AUTOSAR XML (schema 4-2-2)
package /ComponentTypes
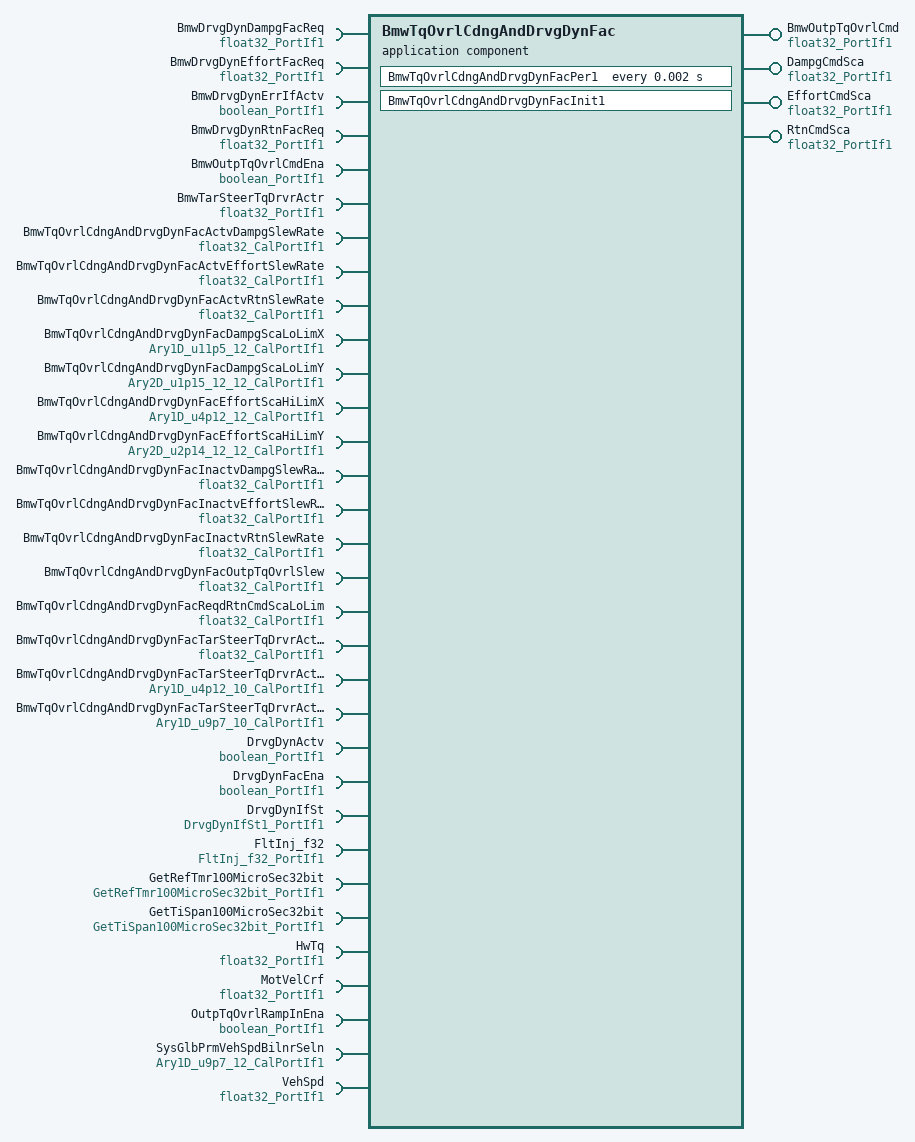
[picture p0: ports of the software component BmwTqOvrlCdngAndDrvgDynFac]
  application sw component type BmwTqOvrlCdngAndDrvgDynFac
    4 x provide port, all with provided-interface=float32_PortIf1:
      BmwOutpTqOvrlCmd: nonqueued-sender-com-spec{data-element=Val, init-value=0}
      DampgCmdSca: nonqueued-sender-com-spec{data-element=Val, init-value=1}
      EffortCmdSca: nonqueued-sender-com-spec{data-element=Val, init-value=1}
      RtnCmdSca: nonqueued-sender-com-spec{data-element=Val, init-value=1}
    32 x require port:
      BmwDrvgDynDampgFacReq: nonqueued-receiver-com-spec{data-element=Val, filter=data-filter-type=ALWAYS, init-value=1}, required-interface=float32_PortIf1
      BmwDrvgDynEffortFacReq: nonqueued-receiver-com-spec{data-element=Val, filter=data-filter-type=ALWAYS, init-value=1}, required-interface=float32_PortIf1
      BmwDrvgDynErrIfActv: nonqueued-receiver-com-spec{data-element=Logl, filter=data-filter-type=ALWAYS, init-value=0}, required-interface=boolean_PortIf1
      BmwDrvgDynRtnFacReq: nonqueued-receiver-com-spec{data-element=Val, filter=data-filter-type=ALWAYS, init-value=1}, required-interface=float32_PortIf1
      BmwOutpTqOvrlCmdEna: nonqueued-receiver-com-spec{data-element=Logl, filter=data-filter-type=ALWAYS, init-value=1}, required-interface=boolean_PortIf1
      BmwTarSteerTqDrvrActr: nonqueued-receiver-com-spec{data-element=Val, filter=data-filter-type=ALWAYS, init-value=0}, required-interface=float32_PortIf1
      BmwTqOvrlCdngAndDrvgDynFacActvDampgSlewRate: parameter-require-com-spec{init-value=500, parameter=Val}, required-interface=float32_CalPortIf1
      BmwTqOvrlCdngAndDrvgDynFacActvEffortSlewRate: parameter-require-com-spec{init-value=500, parameter=Val}, required-interface=float32_CalPortIf1
      BmwTqOvrlCdngAndDrvgDynFacActvRtnSlewRate: parameter-require-com-spec{init-value=500, parameter=Val}, required-interface=float32_CalPortIf1
      BmwTqOvrlCdngAndDrvgDynFacDampgScaLoLimX: parameter-require-com-spec{init-value=[0, 1164, 2327, 3491, 4655, 5818, 6982, 8145, 9309, 10473, 11636, 12800], parameter=Ary1D}, required-interface=Ary1D_u11p5_12_CalPortIf1
      BmwTqOvrlCdngAndDrvgDynFacDampgScaLoLimY: parameter-require-com-spec{init-value=12 x 12 x 0, parameter=Ary2D}, required-interface=Ary2D_u1p15_12_12_CalPortIf1
      BmwTqOvrlCdngAndDrvgDynFacEffortScaHiLimX: parameter-require-com-spec{init-value=[0, 3724, 7447, 11171, 14895, 18618, 22342, 26065, 29789, 33513, 37236, 40960], parameter=Ary1D}, required-interface=Ary1D_u4p12_12_CalPortIf1
      BmwTqOvrlCdngAndDrvgDynFacEffortScaHiLimY: parameter-require-com-spec{init-value=12 x 12 x 32768, parameter=Ary2D}, required-interface=Ary2D_u2p14_12_12_CalPortIf1
      BmwTqOvrlCdngAndDrvgDynFacInactvDampgSlewRate: parameter-require-com-spec{init-value=500, parameter=Val}, required-interface=float32_CalPortIf1
      BmwTqOvrlCdngAndDrvgDynFacInactvEffortSlewRate: parameter-require-com-spec{init-value=500, parameter=Val}, required-interface=float32_CalPortIf1
      BmwTqOvrlCdngAndDrvgDynFacInactvRtnSlewRate: parameter-require-com-spec{init-value=500, parameter=Val}, required-interface=float32_CalPortIf1
      BmwTqOvrlCdngAndDrvgDynFacOutpTqOvrlSlew: parameter-require-com-spec{init-value=2, parameter=Val}, required-interface=float32_CalPortIf1
      BmwTqOvrlCdngAndDrvgDynFacReqdRtnCmdScaLoLim: parameter-require-com-spec{init-value=0, parameter=Val}, required-interface=float32_CalPortIf1
      BmwTqOvrlCdngAndDrvgDynFacTarSteerTqDrvrActrLpFilFrq: parameter-require-com-spec{init-value=0.3, parameter=Val}, required-interface=float32_CalPortIf1
      BmwTqOvrlCdngAndDrvgDynFacTarSteerTqDrvrActrMaxY: parameter-require-com-spec{init-value=[14336, 12288, 10240, 8192, 6144, 4096, 3072, 2048, 1024, 410], parameter=Ary1D}, required-interface=Ary1D_u4p12_10_CalPortIf1
      BmwTqOvrlCdngAndDrvgDynFacTarSteerTqDrvrActrSpdX: parameter-require-com-spec{init-value=[0, 256, 1280, 3200, 6400, 9600, 12800, 19200, 25600, 31872], parameter=Ary1D}, required-interface=Ary1D_u9p7_10_CalPortIf1
      DrvgDynActv: nonqueued-receiver-com-spec{data-element=Logl, filter=data-filter-type=ALWAYS, init-value=0}, required-interface=boolean_PortIf1
      DrvgDynFacEna: nonqueued-receiver-com-spec{data-element=Logl, filter=data-filter-type=ALWAYS, init-value=1}, required-interface=boolean_PortIf1
      DrvgDynIfSt: nonqueued-receiver-com-spec{data-element=Val, filter=data-filter-type=ALWAYS, init-value=128}, required-interface=DrvgDynIfSt1_PortIf1
      FltInj_f32: client-com-spec=Oper, required-interface=FltInj_f32_PortIf1
      GetRefTmr100MicroSec32bit: client-com-spec=Oper, required-interface=GetRefTmr100MicroSec32bit_PortIf1
      GetTiSpan100MicroSec32bit: client-com-spec=Oper, required-interface=GetTiSpan100MicroSec32bit_PortIf1
      HwTq: nonqueued-receiver-com-spec{data-element=Val, filter=data-filter-type=ALWAYS, init-value=0}, required-interface=float32_PortIf1
      MotVelCrf: nonqueued-receiver-com-spec{data-element=Val, filter=data-filter-type=ALWAYS, init-value=0}, required-interface=float32_PortIf1
      OutpTqOvrlRampInEna: nonqueued-receiver-com-spec{data-element=Logl, filter=data-filter-type=ALWAYS, init-value=0}, required-interface=boolean_PortIf1
      SysGlbPrmVehSpdBilnrSeln: parameter-require-com-spec{init-value=[0, 640, 1920, 3840, 7680, 10240, 12800, 15360, 19200, 23040, 25600, 28160], parameter=Ary1D}, required-interface=Ary1D_u9p7_12_CalPortIf1
      VehSpd: nonqueued-receiver-com-spec{data-element=Val, filter=data-filter-type=ALWAYS, init-value=0}, required-interface=float32_PortIf1
    behavior cf40a_InternalBehavior
      ar-typed-per-instance-memorys:
        16 x data, all with sw-calibration-access=READ-ONLY:
          BmwOutpTqOvrlCmdRampCmpl: type=boolean
          BmwOutpTqOvrlCmdStVari: type=float32
          BmwTarSteerTqDrvrActrLpFilStVari: type=FilLpRec1
          DampgCmdScaRateLimrStVari: type=float32
          EffortCmdScaRateLimrStVari: type=float32
          FrznBmwTarSteerTqDrvrActr: type=float32
          FrznSigActv: type=boolean
          LimdCdndTqOvrl: type=float32
          MsgCycTmr: type=uint32
          PrevDampgSlewInProgs: type=boolean
          PrevDrvgDynActv: type=boolean
          PrevDrvgDynIfSt: type=DrvgDynIfSt1
          PrevEffortSlewInProgs: type=boolean
          PrevRtnSlewInProgs: type=boolean
          RampToZeroEnad: type=boolean
          RtnCmdScaRateLimrStVari: type=float32
      init event BmwTqOvrlCdngAndDrvgDynFacInit1_InitEvent: start-on-event=BmwTqOvrlCdngAndDrvgDynFacInit1
      timing event TMT_BmwTqOvrlCdngAndDrvgDynFacPer1: start-on-event=BmwTqOvrlCdngAndDrvgDynFacPer1, period=0.002
      port-api-options:
        enable-take-address=false, error-handling=NO-TRANSFORMER-ERROR-HANDLING, indirect-api=false, port=BmwDrvgDynDampgFacReq
        enable-take-address=false, error-handling=NO-TRANSFORMER-ERROR-HANDLING, indirect-api=false, port=BmwDrvgDynEffortFacReq
        enable-take-address=false, error-handling=NO-TRANSFORMER-ERROR-HANDLING, indirect-api=false, port=BmwDrvgDynErrIfActv
        enable-take-address=false, error-handling=NO-TRANSFORMER-ERROR-HANDLING, indirect-api=false, port=BmwDrvgDynRtnFacReq
        enable-take-address=false, error-handling=NO-TRANSFORMER-ERROR-HANDLING, indirect-api=false, port=BmwOutpTqOvrlCmd
        enable-take-address=false, error-handling=NO-TRANSFORMER-ERROR-HANDLING, indirect-api=false, port=BmwOutpTqOvrlCmdEna
        enable-take-address=false, error-handling=NO-TRANSFORMER-ERROR-HANDLING, indirect-api=false, port=BmwTarSteerTqDrvrActr
        enable-take-address=false, error-handling=NO-TRANSFORMER-ERROR-HANDLING, indirect-api=false, port=BmwTqOvrlCdngAndDrvgDynFacActvDampgSlewRate
        enable-take-address=false, error-handling=NO-TRANSFORMER-ERROR-HANDLING, indirect-api=false, port=BmwTqOvrlCdngAndDrvgDynFacActvEffortSlewRate
        enable-take-address=false, error-handling=NO-TRANSFORMER-ERROR-HANDLING, indirect-api=false, port=BmwTqOvrlCdngAndDrvgDynFacActvRtnSlewRate
        enable-take-address=false, error-handling=NO-TRANSFORMER-ERROR-HANDLING, indirect-api=false, port=BmwTqOvrlCdngAndDrvgDynFacDampgScaLoLimX
        enable-take-address=false, error-handling=NO-TRANSFORMER-ERROR-HANDLING, indirect-api=false, port=BmwTqOvrlCdngAndDrvgDynFacDampgScaLoLimY
        enable-take-address=false, error-handling=NO-TRANSFORMER-ERROR-HANDLING, indirect-api=false, port=BmwTqOvrlCdngAndDrvgDynFacEffortScaHiLimX
        enable-take-address=false, error-handling=NO-TRANSFORMER-ERROR-HANDLING, indirect-api=false, port=BmwTqOvrlCdngAndDrvgDynFacEffortScaHiLimY
        enable-take-address=false, error-handling=NO-TRANSFORMER-ERROR-HANDLING, indirect-api=false, port=BmwTqOvrlCdngAndDrvgDynFacInactvDampgSlewRate
        enable-take-address=false, error-handling=NO-TRANSFORMER-ERROR-HANDLING, indirect-api=false, port=BmwTqOvrlCdngAndDrvgDynFacInactvEffortSlewRate
        enable-take-address=false, error-handling=NO-TRANSFORMER-ERROR-HANDLING, indirect-api=false, port=BmwTqOvrlCdngAndDrvgDynFacInactvRtnSlewRate
        enable-take-address=false, error-handling=NO-TRANSFORMER-ERROR-HANDLING, indirect-api=false, port=BmwTqOvrlCdngAndDrvgDynFacOutpTqOvrlSlew
        enable-take-address=false, error-handling=NO-TRANSFORMER-ERROR-HANDLING, indirect-api=false, port=BmwTqOvrlCdngAndDrvgDynFacReqdRtnCmdScaLoLim
        enable-take-address=false, error-handling=NO-TRANSFORMER-ERROR-HANDLING, indirect-api=false, port=BmwTqOvrlCdngAndDrvgDynFacTarSteerTqDrvrActrLpFilFrq
        enable-take-address=false, error-handling=NO-TRANSFORMER-ERROR-HANDLING, indirect-api=false, port=BmwTqOvrlCdngAndDrvgDynFacTarSteerTqDrvrActrMaxY
        enable-take-address=false, error-handling=NO-TRANSFORMER-ERROR-HANDLING, indirect-api=false, port=BmwTqOvrlCdngAndDrvgDynFacTarSteerTqDrvrActrSpdX
        enable-take-address=false, error-handling=NO-TRANSFORMER-ERROR-HANDLING, indirect-api=false, port=DampgCmdSca
        enable-take-address=false, error-handling=NO-TRANSFORMER-ERROR-HANDLING, indirect-api=false, port=DrvgDynActv
        enable-take-address=false, error-handling=NO-TRANSFORMER-ERROR-HANDLING, indirect-api=false, port=DrvgDynFacEna
        enable-take-address=false, error-handling=NO-TRANSFORMER-ERROR-HANDLING, indirect-api=false, port=DrvgDynIfSt
        enable-take-address=false, error-handling=NO-TRANSFORMER-ERROR-HANDLING, indirect-api=false, port=EffortCmdSca
        enable-take-address=false, error-handling=NO-TRANSFORMER-ERROR-HANDLING, indirect-api=false, port=FltInj_f32
        enable-take-address=false, error-handling=NO-TRANSFORMER-ERROR-HANDLING, indirect-api=false, port=GetRefTmr100MicroSec32bit
        enable-take-address=false, error-handling=NO-TRANSFORMER-ERROR-HANDLING, indirect-api=false, port=GetTiSpan100MicroSec32bit
        enable-take-address=false, error-handling=NO-TRANSFORMER-ERROR-HANDLING, indirect-api=false, port=HwTq
        enable-take-address=false, error-handling=NO-TRANSFORMER-ERROR-HANDLING, indirect-api=false, port=MotVelCrf
        enable-take-address=false, error-handling=NO-TRANSFORMER-ERROR-HANDLING, indirect-api=false, port=OutpTqOvrlRampInEna
        enable-take-address=false, error-handling=NO-TRANSFORMER-ERROR-HANDLING, indirect-api=false, port=RtnCmdSca
        enable-take-address=false, error-handling=NO-TRANSFORMER-ERROR-HANDLING, indirect-api=false, port=SysGlbPrmVehSpdBilnrSeln
        enable-take-address=false, error-handling=NO-TRANSFORMER-ERROR-HANDLING, indirect-api=false, port=VehSpd
      runnable BmwTqOvrlCdngAndDrvgDynFacInit1
      runnable BmwTqOvrlCdngAndDrvgDynFacPer1
        data-receive-point-by-arguments:
          13 x access:
            REC_BmwDrvgDynDampgFacReq_Val: accessed-variable=BmwDrvgDynDampgFacReq.Val
            REC_BmwDrvgDynEffortFacReq_Val: accessed-variable=BmwDrvgDynEffortFacReq.Val
            REC_BmwDrvgDynErrIfActv_Logl: accessed-variable=BmwDrvgDynErrIfActv.Logl
            REC_BmwDrvgDynRtnFacReq_Val: accessed-variable=BmwDrvgDynRtnFacReq.Val
            REC_BmwOutpTqOvrlCmdEna_Logl: accessed-variable=BmwOutpTqOvrlCmdEna.Logl
            REC_BmwTarSteerTqDrvrActr_Val: accessed-variable=BmwTarSteerTqDrvrActr.Val
            REC_DrvgDynActv_Logl: accessed-variable=DrvgDynActv.Logl
            REC_DrvgDynFacEna_Logl: accessed-variable=DrvgDynFacEna.Logl
            REC_DrvgDynIfSt_Val: accessed-variable=DrvgDynIfSt.Val
            REC_HwTq_Val: accessed-variable=HwTq.Val
            REC_MotVelCrf_Val: accessed-variable=MotVelCrf.Val
            REC_OutpTqOvrlRampInEna_Logl: accessed-variable=OutpTqOvrlRampInEna.Logl
            REC_VehSpd_Val: accessed-variable=VehSpd.Val
        data-send-points:
          4 x access:
            SEND_BmwOutpTqOvrlCmd_Val: accessed-variable=BmwOutpTqOvrlCmd.Val
            SEND_DampgCmdSca_Val: accessed-variable=DampgCmdSca.Val
            SEND_EffortCmdSca_Val: accessed-variable=EffortCmdSca.Val
            SEND_RtnCmdSca_Val: accessed-variable=RtnCmdSca.Val
        sync call SC_FltInj_f32_PortIf1_Oper: operation=FltInj_f32.Oper, timeout=0
        sync call SC_GetRefTmr100MicroSec32bit_PortIf1_Oper: operation=GetRefTmr100MicroSec32bit.Oper, timeout=0
        sync call SC_GetTiSpan100MicroSec32bit_PortIf1_Oper: operation=GetTiSpan100MicroSec32bit.Oper, timeout=0
  swc implementation BmwTqOvrlCdngAndDrvgDynFac_Implementation: behavior=cf40a_InternalBehavior
    code-descriptors:
      code Default: artifact-descriptors=autosar-engineering-object={short-label=Default, category=SWSRC}
